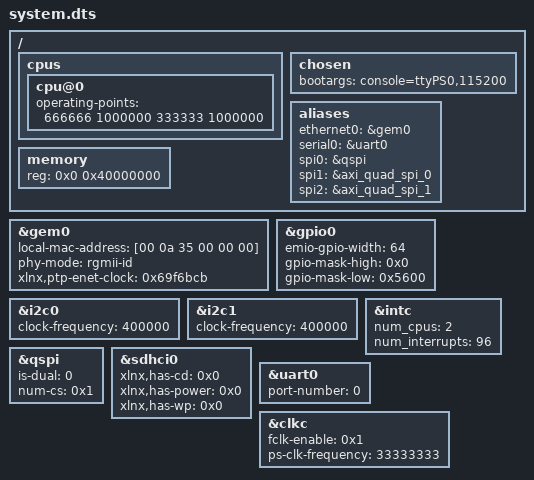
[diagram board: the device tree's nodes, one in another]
/*
 * CAUTION: This file is automatically generated by Xilinx.
 * Version:  
 * Today is: Tue Jan 08 10:32:49 2019
*/


/dts-v1/;
/include/ "zynq-7000.dtsi"
/include/ "pl.dtsi"
/ {
	cpus {
		cpu@0 {
			operating-points = <666666 1000000 333333 1000000>;
		};
	};
	chosen {
		bootargs = "console=ttyPS0,115200";
	};
	aliases {
		ethernet0 = &gem0;
		serial0 = &uart0;
		spi0 = &qspi;
		spi1 = &axi_quad_spi_0;
		spi2 = &axi_quad_spi_1;
	};
	memory {
		device_type = "memory";
		reg = <0x0 0x40000000>;
	};
};
&gem0 {
	local-mac-address = [00 0a 35 00 00 00];
	phy-mode = "rgmii-id";
	status = "okay";
	xlnx,ptp-enet-clock = <0x69f6bcb>;
};
&gpio0 {
	emio-gpio-width = <64>;
	gpio-mask-high = <0x0>;
	gpio-mask-low = <0x5600>;
};
&i2c0 {
	clock-frequency = <400000>;
	status = "okay";
};
&i2c1 {
	clock-frequency = <400000>;
	status = "okay";
};
&intc {
	num_cpus = <2>;
	num_interrupts = <96>;
};
&qspi {
	is-dual = <0>;
	num-cs = <0x1>;
	status = "okay";
};
&sdhci0 {
	status = "okay";
	xlnx,has-cd = <0x0>;
	xlnx,has-power = <0x0>;
	xlnx,has-wp = <0x0>;
};
&uart0 {
	device_type = "serial";
	port-number = <0>;
	status = "okay";
};
&clkc {
	fclk-enable = <0x1>;
	ps-clk-frequency = <33333333>;
};
